# RZT2ME register map
Vendor: Renesas Electronics Corporation; Series: RZT; File version: 1.00.00
CPU: other r0p0, little endian, MPU, no FPU, VTOR, 4 interrupt priority bits, 624 interrupts
Registers are 32-bit, read-write, reset 0x0 unless marked. A register's access mark holds for its fields unless they carry their own. Offsets are from the block's base; [hi:lo] are bit positions; {n}, {i} and the like mark numbered series.

## SEM — Semaphore
Base 0x80281000
0x00 SYTSEMFEN — Semaphore Enable Register
  [0] SEMFEN — Semaphore Enable
    0=Read clear function disabled; 1=Read clear function enabled
{0x10+4i} SYTSEMF{i} (i=0..7) — Semaphore Register {i}
  [0] SEMF — Semaphore
    0=Resource is used; 1=Resource is not used

## ELO — Evnet Link Option Setting
Base 0x80281200
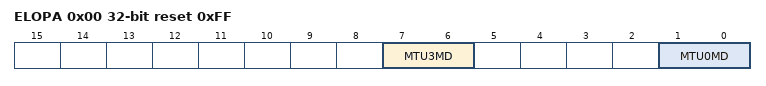
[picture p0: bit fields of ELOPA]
0x00 ELOPA reset 0xFF — Event Link Option Setting Register A
  [7:6] MTU3MD — MTU3 Operation Select
    0=Counting is started; 1=Counting is restarted; 2=Input capture (The MTU3.TCNT value is captured into MTU3.TGRA.); 3=Event is disabled
  [1:0] MTU0MD — MTU0 Operation Select
    0=Counting is started; 1=Counting is restarted; 2=Input capture (The MTU0.TCNT value is captured into MTU0.TGRA.); 3=Event is disabled
0x04 ELOPB reset 0xFF — Event Link Option Setting Register B
  [1:0] MTU4MD — MTU4 Operation Select
    0=Counting is started; 1=Counting is restarted; 2=Input capture (The MTU4.TCNT value is captured into MTU4.TGRA.); 3=Event is disabled

## RWP_NS — Register Write Protection for Non-safety Area
Base 0x80281A10
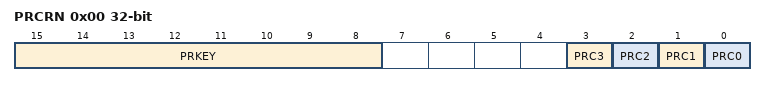
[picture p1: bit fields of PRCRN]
0x00 PRCRN — Non_Safety Area Protect Register
  [15:8] PRKEY wo — PRC Key Code
  [n] PRC{n} (n=0..3) — Protect {n}
    0=Write disabled; 1=Write enabled

## XSPI0_MISC — xSPI Voltage and Size UNIT0 Registers
Base 0x80281C00
Same registers: XSPI1_MISC 0x80281D00
0x04 CS0ENDAD reset 0x400FFFFF (reset mask 0xF7FFFFFF) — xSPI CS0 End Address Register
  [31:0] CS0_END_ADD — CS0 (slave 0) area end address
0x08 CS1STRAD reset 0x44000000 (reset mask 0xF7FFFFFF) — xSPI CS1 Start Address Register
  [31:0] CS1_STR_ADD — CS1 (slave 1) area start address
0x0C CS1ENDAD reset 0x440FFFFF (reset mask 0xF7FFFFFF) — xSPI CS1 End Address Register
  [31:0] CS1_END_ADD — CS1 (slave 0) area end address

## OTFD0 — On-The-Fly Decryption UNIT0 Registers
Base 0x81290000
Same registers: OTFD1 0x81291000
0x00 CONVAREAST — Conversion Area Start Address Register
  [31:12] CONVAREAST — The first address of the decryption processing area. The actual AXI address is CONVAREAST[31:12] * 0x1000
0x04 CONVAREAED — Conversion Area End Address Register
  [31:12] CONVAREAED — The end address of the decryption processing area. The actual AXI address is (CONVAREAED[31:12] + 1) * 0x1000 - 1
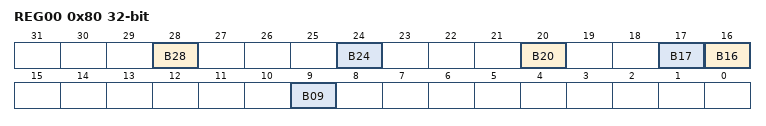
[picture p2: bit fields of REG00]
0x80 REG00 — Register 0
  [28] B28 — Bit 28
  [24] B24 — Bit 24
  [20] B20 — Bit 20
  [17] B17 — Bit 17
  [16] B16 — Bit 16
  [9] B09 — Bit 09
0x8C REG03 reset 0xF — Register 03
  [31:0] B00 — Bit 0
0x94 ST reset 0xF — Status

## OTP — One-Time Programmable Memory
Base 0x81028000
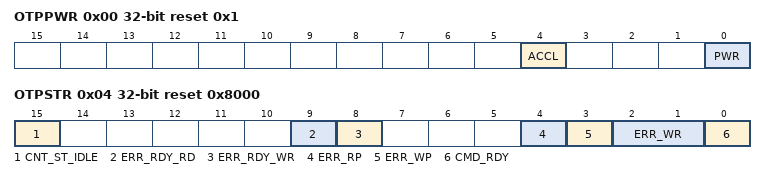
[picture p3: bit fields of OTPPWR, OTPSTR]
0x00 OTPPWR reset 0x1 — OTP Power Control Register
  [4] ACCL — Selects OTP access I/F
    0=Not selected; 1=Selected
  [0] PWR — OTP power on/off setting
    0=Power off; 1=Power on
0x04 OTPSTR reset 0x8000 — OTP Access Status Register
  [15] CNT_ST_IDLE ro — Indicates status of OTP controller
    0=Busy; 1=Idle
  [9] ERR_RDY_RD — OTP read command ready error
  [8] ERR_RDY_WR — OTP write command ready error
  [4] ERR_RP ro — Read protection error
  [3] ERR_WP ro — Write protection error
  [2:1] ERR_WR ro — OTP write status
    0=PASS; 1=Fail due to overwrites; 2=Fail due to compare mismatch; 3=Fail due to overwrites and compare mismatch
  [0] CMD_RDY ro — Indicates whether OTP controller is ready to receive command or not.
    0=Not ready; 1=Ready
0x08 OTPSTAWR — OTP Write Command Register
  [0] STAWR — OTP write start
0x0C OTPADRWR — OTP Write Address Register
  [8:0] ADRWR — OTP write address
0x10 OTPDATAWR — OTP Write Data Register
  [15:0] DATAWR — OTP write data
0x14 OTPADRRD — OTP Read Address Register
  [8:0] ADRRD — OTP read address
0x18 OTPDATARD ro — OTP Read Data Register
  [15:0] DATARD — OTP read data
